# USB0_VBP2AHB_WRAP_CONTROLLER_VBP_USB3_CORE_GBL register map
Vendor: Texas Instruments
Registers are 32-bit, read-write, reset 0x0 unless marked. A register's access mark holds for its fields unless they carry their own. Offsets are as the file gives them; [hi:lo] are bit positions; {n}, {i} and the like mark numbered series; <NAME> marks a mode.

## USB0_VBP2AHB_WRAP_CONTROLLER_VBP_USB3_CORE_GBL (part 3 of 4)
0x20 VBP2AHB_WRAP__CONTROLLER_VBP__USB3_CORE_GBL_GSNPSID ro reset 0x5533330B — Global Synopsys ID Register This is a read-only register that contains the release number of the controller.
  [31:0] SYNOPSYSID — Synopsys ID - SynopsysID[31:16] indicates Core Identification Number. 0x5533 is ASCII for U3 [DWC_usb3]. - SynopsysID[15:0] indicates the release number. Current Release is 3.30a. Software uses this register to configure release-specific features in the driver.
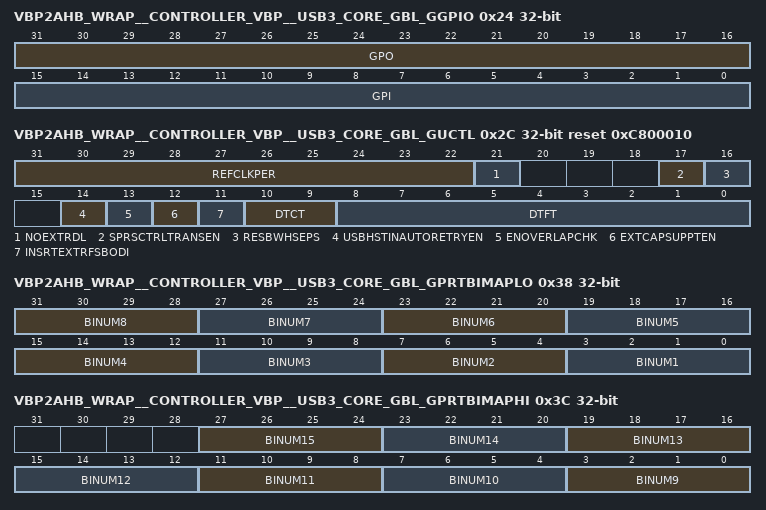
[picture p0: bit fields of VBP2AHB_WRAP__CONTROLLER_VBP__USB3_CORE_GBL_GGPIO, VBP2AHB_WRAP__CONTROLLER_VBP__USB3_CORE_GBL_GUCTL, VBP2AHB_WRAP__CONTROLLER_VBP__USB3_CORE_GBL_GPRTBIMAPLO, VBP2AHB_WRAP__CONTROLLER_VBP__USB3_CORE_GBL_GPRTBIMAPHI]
0x24 VBP2AHB_WRAP__CONTROLLER_VBP__USB3_CORE_GBL_GGPIO access per field — Global General Purpose Input/Output Register The application can use this register for general purpose input and output ports or for debugging.
  [31:16] GPO rw — General Purpose Output The value of this field is driven out on the gp_out[15:0] output port.
  [15:0] GPI ro — General Purpose Input The read value of this field reflects the gp_in[15:0] input signal value. Note: Register bit-bash test should not check for reset value of this field since its not predictable. depends on the gp_in port.
0x28 VBP2AHB_WRAP__CONTROLLER_VBP__USB3_CORE_GBL_GUID — Global User ID Register This is a read/write register containing the User ID. The power-on value for this register is specified as the User Identification Register. Power-on value during coreConsultant configuration (parameter DWC_USB3_USERID). This register can be used in the following ways: - To store the version or revision of your system. - To store hardware configurations that are outside the controller. - As a scratch register.
  [31:0] USERID — USERID Application-programmable ID field.
0x2C VBP2AHB_WRAP__CONTROLLER_VBP__USB3_CORE_GBL_GUCTL reset 0xC800010 — Global User Control Register: This register provides a few options for the software to control the controller behavior in the Host mode. Most of the options are used to improve host inter-operability with different devices.
  [31:22] REFCLKPER — REFCLKPER This field indicates in terms of nano seconds the period of ref_clk. The default value of this register is set to 'h8 [8ns/125 MHz]. This field needs to be updated during power-on initialization, if GCTL.SOFITPSYNC or GFLADJ.GFLADJ_REFCLK_LPM_SEL is set to '1'. The programmable maximum value is 62ns, and the minimum value is 8ns. You must use a reference clock with a period that is an integer multiple, so that ITP can meet the jitter margin of 32ns. The allowable ref_clk frequencies whose period is not integer multiples are 16/17/19.2/24/39.7MHz. This field must not be set to '0' at any time. If you never plan to use this feature, then set this field to 'h8, the default value.
  [21] NOEXTRDL — No Extra Delay Between SOF and the First Packet[NoExtrDl] Some HS devices misbehave when the host sends a packet immediately after a SOF. However, adding an extra delay between a SOF and the first packet can reduce the USB data rate and performance. This bit is used to control whether the host must wait for 2 microseconds before it sends the first packet after a SOF, or not. User can set this bit to one to improve the performance if those problematic devices are not a concern in the user's host environment. - 1'b0: Host waits for 2 microseconds after a SOF before it sends the first USB packet. - 1'b1: Host doesn't wait after a SOF before it sends the first USB packet.
  [17] SPRSCTRLTRANSEN — Sparse Control Transaction Enable Some devices are slow in responding to Control transfers. Scheduling multiple transactions in one microframe/frame can cause these devices to misbehave. If this bit is set to 1'b1, the host controller schedules transactions for a Control transfer in different microframes/frames.
  [16] RESBWHSEPS — Reserving 85% Bandwidth for HS Periodic EPs [ResBwHSEPS] By default, HC reserves 800f the bandwidth for periodic EPs. If this bit is set, the bandwidth is relaxed to 85% to accommodate two high speed, high bandwidth ISOC EPs. USB 2.0 required 800andwidth allocated for ISOC traffic. If two High-bandwidth ISOC devices [HD Webcams] are connected, and if each requires 1024-bytes X 3 packets per Micro-Frame, then the bandwidth required is around 82%. If this bit is set, then it is possible to connect two Webcams of 1024bytes X 3 paylod per Micro-Frame each. Otherwise, you may have to reduce the resolution of the Webcams. This bit is valid in Host and DRD configuration and is used in host mode operation only. Ignore this bit in device mode.
  [14] USBHSTINAUTORETRYEN — Host IN Auto Retry [USBHstInAutoRetryEn] When set, this field enables the Auto Retry feature. For IN transfers [non-isochronous] that encounter data packets with CRC errors or internal overrun scenarios, the auto retry feature causes the Host controller to reply to the device with a non-terminating retry ACK [that is, an ACK transaction packet with Retry = 1 and NumP != 0]. If the Auto Retry feature is disabled [default], the controller will respond with a terminating retry ACK [that is, an ACK transaction packet with Retry = 1 and NumP = 0]. - 1'b0: Auto Retry Disabled - 1'b1: Auto Retry Enabled Note: When enabling Auto Retry feature, if the system latency is large enough to cause the internal PSQ full [PSQ can be full as the result of messages not being processed because of pending fetches before flushing the TxQ due to NRDY/ERDY conditions], then the host controller can generate a transaction error.
  [13] ENOVERLAPCHK — Enable Check for LFPS Overlap During Remote Ux Exit: If this bit is set to, - 1'b1: The SuperSpeed link when exiting U1/U2/U3 waits for either the remote link LFPS or TS1/TS2 training symbols before it confirms that the LFPS handshake is complete. This is done to handle the case where the LFPS glitch causes the link to start exiting from the low power state. Looking for the LFPS overlap makes sure that the link partner also sees the LFPS. - 1'b0: When the link exists U1/U2/U3 because of a remote exit, it does not look for an LFPS overlap.
  [12] EXTCAPSUPPTEN — External Extended Capability Support Enable [ExtCapSuptEN] When set, this field enables extended capabilities to be implemented outside the controller. When the ExtCapSupEN is set and the Debug Capability is enabled, the Next Capability pointer in Debug Capability returns 16. A read to the first DWORD of the last internal extended capability [the xHCI Supported Protocol Capability for USB 3.0 when the Debug Capability is not enabled] returns a value of 4 in the Next Capability Pointer field. This indicates to software that there is another capability four DWORDs after this capability [for example, at address N+16 where N is the address of this DWORD]. If enabled, an external address decoder that snoops the xHC target interface must be implemented. If it sees an access to N+16 or greater, the target access is re-routed to a piece of hardware which returns the external capability pointer register of the new capability and also handles reads/writes to this new capability and the side effects. If disabled, a read to the first DWORD of the last internal extended capability returns 0 in the 'Next Capability Pointer field. This indicates there are no more capabilities.
  [11] INSRTEXTRFSBODI — Insert Extra Delay Between FS Bulk OUT Transactions [InsrtExtrFSBODl]. Some FS devices are slow to receive Bulk OUT data and can get stuck when there are consecutive Bulk OUT transactions with short inter-transaction delays. This bit is used to control whether the host inserts extra delay between consecutive Bulk OUT transactions to a FS Endpoint. - 1'b0: Host doesn't insert extra delay between consecutive Bulk OUT transactions to a FS Endpoint. - 1'b1: Host inserts about 12us extra delay between consecutive Bulk OUT transactions to a FS Endpoint to work around the device issue. Note: Setting this bit to one will reduce the Bulk OUT transfer performance for most of the FS devices.
  [10:9] DTCT — Device Timeout Coarse Tuning [DTCT] This field is a Host mode parameter which determines how long the host waits for a response from device before considering a timeout. The controller first checks the DTCT value. If it is 0, then the timeout value is defined by the DTFT. If it is non-zero, then it uses the following timeout values: - 2'b00: 0 usec -> use DTFT value instead - 2'b01: 500 usec - 2'b10: 1.5 msec - 2'b11: 6.5 msec Note: When the system latency is larger than the programmed DTCT/DTFT value, if the host controller is not able to accept certain transactions on the bus [because of system bus delays], the controller may not release header credits which in turn can cause the host to report a transaction error. Therefore, program this value to be larger than your system delay.
  [8:0] DTFT — Device Timeout Fine Tuning [DTFT] This field is a Host mode parameter which determines how long the host waits for a response from device before considering a timeout. For the DTFT field to take effect, DTCT must be set to 2'b00. The DTFT value is the number of 125 MHz clocks * 256 to count before considering a device timeout. The minimum value of DTFT is 2. For example, if the mac3_clk is 125 MHz clk [8 ns period], this is calculated as follows: [DTFT value] * 256 * [8 ns] Quick Reference: - if DTFT = 0x2, 2*256*8 = 4usec timeout - if DTFT = 0x5, 5*256*8 = 10usec timeout - if DTFT = 0xA, 10*256*8 = 20usec timeout - if DTFT = 0x10, 16*256*8 = 32usec timeout - if DTFT = 0x19, 25*256*8 = 51usec timeout - if DTFT = 0x31, 49*256*8 = 100usec timeout - if DTFT = 0x62, 98*256*8 = 200usec timeout Note: When the system latency is larger than the programmed DTCT/DTFT value, if the host controller is not able to accept certain transactions on the bus [because of system bus delays], the controller may not release header credits which in turn can cause the host to report a transaction error. Therefore, program this value to be larger than your system delay.
0x30 VBP2AHB_WRAP__CONTROLLER_VBP__USB3_CORE_GBL_GBUSERRADDRLO ro — Gobal SoC Bus Error Address Register - Low This is an alternate register for the GBUSERRADDR register.
  [31:0] BUSERRADDR — Bus Address - Low [BusAddrLo] This register contains the lower 32 bits of the first bus address that encountered a SoC bus error. It is valid when the GSTS.BusErrAddrVld field is 1. It can only be cleared by resetting the controller. Note: Only supported in AHB and AXI configurations.
0x34 VBP2AHB_WRAP__CONTROLLER_VBP__USB3_CORE_GBL_GBUSERRADDRHI ro — Gobal SoC Bus Error Address Register - High This is an alternate register for the GBUSERRADDR register.
  [31:0] BUSERRADDR — Bus Address - High [BusAddrHi] This register contains the higher 32 bits of the first bus address that encountered a SoC bus error. It is valid when the GSTS.BusErrAddrVld field is 1. It can only be cleared by resetting the controller. Note: Only supported in AHB and AXI configurations.
0x38 VBP2AHB_WRAP__CONTROLLER_VBP__USB3_CORE_GBL_GPRTBIMAPLO access per field — Global SS Port to Bus Instance Mapping Register - Low This is an alternate register for the GPRTBIMAP register. Register fields are read-write with respect to number of port instantiated. writeAsRead constraint is added to limit side effects for unused fields. For a configuration with number of USB 3.0 ports same as number of SS Bus Instances, do not remap during debug session. If you remap for some reason, then the debug host must be connected to a port which has a dedicated SS Bus Instance. For example, if DWC_USB3_NUM_U3_ROOT_PORTS =3 and DWC_USB3_NUM_SS_USB_INSTANCES=3, and software maps the first SS port to the first SS BI and the second/third port to the second BI, then the debug host can be connected to the first port only. Note: For reset values, refer to the corresponding values in the GPRTBIMAP register.
  [4n-1:4n-4] BINUM{n} ro (n=2..8) — BINUM{n}: SS USB Instance Number for Port {n}. Application-programmable ID field.
  [3:0] BINUM1 rw — BINUM1: SS USB Instance Number for Port 1. Application-programmable ID field.
0x3C VBP2AHB_WRAP__CONTROLLER_VBP__USB3_CORE_GBL_GPRTBIMAPHI ro — Global SS Port to Bus Instance Mapping Register - High This is an alternate register for the GPRTBIMAP register. For a configuration with number of USB 3.0 ports same as number of SS Bus Instances, do not remap during debug session. If you remap for some reason, then the debug host must be connected to a port which has a dedicated SS Bus Instance. For example, if DWC_USB3_NUM_U3_ROOT_PORTS =3 and DWC_USB3_NUM_SS_USB_INSTANCES=3, and software maps the first SS port to the first SS BI and the second/third port to the second BI, then the debug host can be connected to the first port only. Note: For reset values, refer to the corresponding values in the GPRTBIMAP register.
  [4n-33:4n-36] BINUM{n} (n=9..15) — BINUM{n}: SS USB Instance Number for Port {n}. Application-programmable ID field.
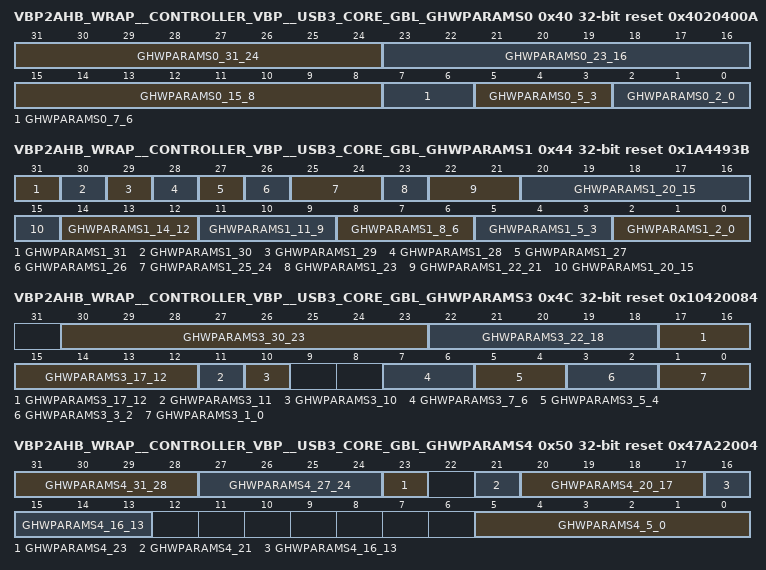
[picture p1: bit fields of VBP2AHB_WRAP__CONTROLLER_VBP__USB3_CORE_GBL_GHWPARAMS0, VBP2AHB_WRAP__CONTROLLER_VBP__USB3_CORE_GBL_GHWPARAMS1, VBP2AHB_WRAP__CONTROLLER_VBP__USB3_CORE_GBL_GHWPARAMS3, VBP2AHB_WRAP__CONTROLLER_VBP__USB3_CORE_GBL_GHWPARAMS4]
0x40 VBP2AHB_WRAP__CONTROLLER_VBP__USB3_CORE_GBL_GHWPARAMS0 ro reset 0x4020400A — Global Hardware Parameters Register 0 This register contains the hardware configuration options that you can select in the coreConsultant GUI. For a description of each parameter, refer to the Parameter Descriptions chapter in the Databook. This information is also available in coreConsultant by right-clicking the parameter label and selecting What's This or by clicking the Help tab. Note: Some of the global hardware parameters are not currently modifiable in coreConsultant. These settings are in the <workspace>/src/DWC_usb3_params.v file. you must not change them.
  [31:24] GHWPARAMS0_31_24 — DWC_USB3_AWIDTH
  [23:16] GHWPARAMS0_23_16 — DWC_USB3_SDWIDTH
  [15:8] GHWPARAMS0_15_8 — DWC_USB3_MDWIDTH
  [7:6] GHWPARAMS0_7_6 — DWC_USB3_SBUS_TYPE
  [5:3] GHWPARAMS0_5_3 — DWC_USB3_MBUS_TYPE
  [2:0] GHWPARAMS0_2_0 — DWC_USB3_MODE
0x44 VBP2AHB_WRAP__CONTROLLER_VBP__USB3_CORE_GBL_GHWPARAMS1 ro reset 0x1A4493B — Global Hardware Parameters Register 1 This register contains the hardware configuration options that you can select in the coreConsultant GUI. For a description of each parameter, refer to the Parameter Descriptions chapter in the Databook. This information is also available in coreConsultant by right-clicking the parameter label and selecting What's This or by clicking the Help tab. Note: Some of the global hardware parameters are not currently modifiable in coreConsultant. These settings are in the <workspace>/src/DWC_usb3_params.v file. you must not change them.
  [31] GHWPARAMS1_31 — DWC_USB3_EN_DBC
  [30] GHWPARAMS1_30 — DWC_USB3_RM_OPT_FEATURES
  [29] GHWPARAMS1_29 — Reserved1
  [28] GHWPARAMS1_28 — DWC_USB3_RAM_BUS_CLKS_SYNC
  [27] GHWPARAMS1_27 — DWC_USB3_MAC_RAM_CLKS_SYNC
  [26] GHWPARAMS1_26 — DWC_USB3_MAC_PHY_CLKS_SYNC
  [25:24] GHWPARAMS1_25_24 — DWC_USB3_EN_PWROPT
  [23] GHWPARAMS1_23 — DWC_USB3_SPRAM_TYP
  [22:21] GHWPARAMS1_22_21 — DWC_USB3_NUM_RAMS
  [20:15] GHWPARAMS1_20_15 — DWC_USB3_DEVICE_NUM_INT For details on DWC_USB3_DEVICE_NUM_INT, refer to <workspace>/src/DWC_usb3_params.v file.
  [14:12] GHWPARAMS1_14_12 — DWC_USB3_ASPACEWIDTH
  [11:9] GHWPARAMS1_11_9 — DWC_USB3_REQINFOWIDTH
  [8:6] GHWPARAMS1_8_6 — DWC_USB3_DATAINFOWIDTH
  [5:3] GHWPARAMS1_5_3 — DWC_USB3_BURSTWIDTH-1
  [2:0] GHWPARAMS1_2_0 — DWC_USB3_IDWIDTH-1
0x48 VBP2AHB_WRAP__CONTROLLER_VBP__USB3_CORE_GBL_GHWPARAMS2 ro — Global Hardware Parameters Register 2 This register contains the hardware configuration options that you can select in the coreConsultant GUI. For a description of each parameter, refer to the Parameter Descriptions chapter in the Databook. This information is also available in coreConsultant by right-clicking the parameter label and selecting What's This or by clicking the Help tab. Note: Some of the global hardware parameters are not currently modifiable in coreConsultant. These settings are in the <workspace>/src/DWC_usb3_params.v file. you must not change them.
  [31:0] GHWPARAMS2_31_0 — DWC_USB3_USERID
0x4C VBP2AHB_WRAP__CONTROLLER_VBP__USB3_CORE_GBL_GHWPARAMS3 ro reset 0x10420084 — Global Hardware Parameters Register 3 This register contains the hardware configuration options that you can select in the coreConsultant GUI. For a description of each parameter, refer to the Parameter Descriptions chapter in the Databook. This information is also available in coreConsultant by right-clicking the parameter label and selecting What's This or by clicking the Help tab. Note: Some of the global hardware parameters are not currently modifiable in coreConsultant. These settings are in the <workspace>/src/DWC_usb3_params.v file. you must not change them.
  [30:23] GHWPARAMS3_30_23 — DWC_USB3_CACHE_TOTAL_XFER_RESOURCES
  [22:18] GHWPARAMS3_22_18 — DWC_USB3_NUM_IN_EPS
  [17:12] GHWPARAMS3_17_12 — DWC_USB3_NUM_EPS
  [11] GHWPARAMS3_11 — DWC_USB3_ULPI_CARKIT
  [10] GHWPARAMS3_10 — DWC_USB3_VENDOR_CTL_INTERFACE
  [7:6] GHWPARAMS3_7_6 — DWC_USB3_HSPHY_DWIDTH
  [5:4] GHWPARAMS3_5_4 — DWC_USB3_FSPHY_INTERFACE
  [3:2] GHWPARAMS3_3_2 — DWC_USB3_HSPHY_INTERFACE
  [1:0] GHWPARAMS3_1_0 — DWC_USB3_SSPHY_INTERFACE
0x50 VBP2AHB_WRAP__CONTROLLER_VBP__USB3_CORE_GBL_GHWPARAMS4 ro reset 0x47A22004 — Global Hardware Parameters Register 4 This register contains the hardware configuration options that you can select in the coreConsultant GUI. For a description of each parameter, refer to the Parameter Descriptions chapter in the Databook. This information is also available in coreConsultant by right-clicking the parameter label and selecting What's This or by clicking the Help tab. Note: Some of the global hardware parameters are not currently modifiable in coreConsultant. These settings are in the <workspace>/src/DWC_usb3_params.v file. you must not change them.
  [31:28] GHWPARAMS4_31_28 — DWC_USB3_BMU_LSP_DEPTH
  [27:24] GHWPARAMS4_27_24 — DWC_USB3_BMU_PTL_DEPTH-1
  [23] GHWPARAMS4_23 — DWC_USB3_EN_ISOC_SUPT
  [21] GHWPARAMS4_21 — DWC_USB3_EXT_BUFF_CONTROL
  [20:17] GHWPARAMS4_20_17 — DWC_USB3_NUM_SS_USB_INSTANCES
  [16:13] GHWPARAMS4_16_13 — DWC_USB3_HIBER_SCRATCHBUFS Number of external scratchpad buffers the controller requires to save its internal state in the device mode. Each buffer is assumed to be 4KB. The scratchpad buffer array must have this many buffer pointers.
  [5:0] GHWPARAMS4_5_0 — DWC_USB3_CACHE_TRBS_PER_TRANSFER
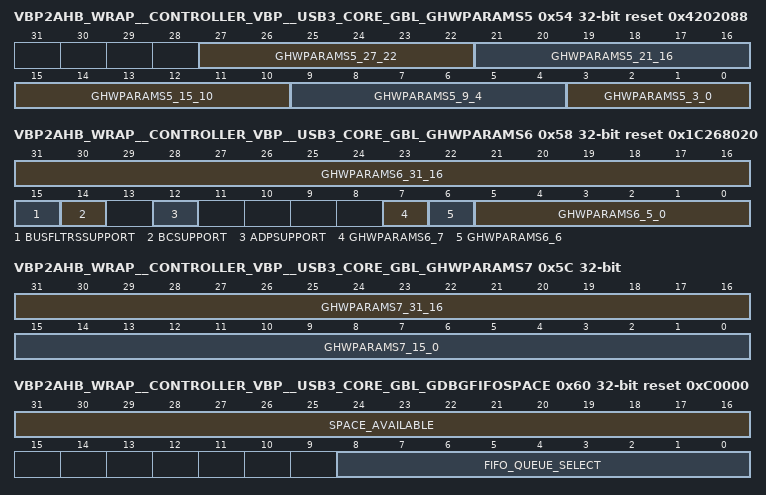
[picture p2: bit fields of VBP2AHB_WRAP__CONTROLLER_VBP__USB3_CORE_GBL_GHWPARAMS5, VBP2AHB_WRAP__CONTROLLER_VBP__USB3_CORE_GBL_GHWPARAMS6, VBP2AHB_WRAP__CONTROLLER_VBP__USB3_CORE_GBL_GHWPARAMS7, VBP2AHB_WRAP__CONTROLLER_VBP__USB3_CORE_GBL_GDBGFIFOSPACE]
0x54 VBP2AHB_WRAP__CONTROLLER_VBP__USB3_CORE_GBL_GHWPARAMS5 ro reset 0x4202088 — Global Hardware Parameters Register 5 This register contains the hardware configuration options that you can select in the coreConsultant GUI. For a description of each parameter, refer to the Parameter Descriptions chapter in the Databook. This information is also available in coreConsultant by right-clicking the parameter label and selecting What's This or by clicking the Help tab. Note: Some of the global hardware parameters are not currently modifiable in coreConsultant. These settings are in the <workspace>/src/DWC_usb3_params.v file. you must not change them.
  [27:22] GHWPARAMS5_27_22 — DWC_USB3_DFQ_FIFO_DEPTH
  [21:16] GHWPARAMS5_21_16 — DWC_USB3_DWQ_FIFO_DEPTH
  [15:10] GHWPARAMS5_15_10 — DWC_USB3_TXQ_FIFO_DEPTH
  [9:4] GHWPARAMS5_9_4 — DWC_USB3_RXQ_FIFO_DEPTH
  [3:0] GHWPARAMS5_3_0 — DWC_USB3_BMU_BUSGM_DEPTH
0x58 VBP2AHB_WRAP__CONTROLLER_VBP__USB3_CORE_GBL_GHWPARAMS6 ro reset 0x1C268020 — Global Hardware Parameters Register 6 This register contains the hardware configuration options that you can select in the coreConsultant GUI. For a description of each parameter, refer to the Parameter Descriptions chapter in the Databook. This information is also available in coreConsultant by right-clicking the parameter label and selecting What's This or by clicking the Help tab. Note: Some of the global hardware parameters are not currently modifiable in coreConsultant. These settings are in the <workspace>/src/DWC_usb3_params.v file. you must not change them.
  [31:16] GHWPARAMS6_31_16 — DWC_USB3_RAM0_DEPTH
  [15] BUSFLTRSSUPPORT — DWC_USB3_EN_BUS_FILTERS
  [14] BCSUPPORT — DWC_USB3_EN_BC
  [12] ADPSUPPORT — DWC_USB3_EN_ADP
  [7] GHWPARAMS6_7 — DWC_USB3_EN_FPGA
  [6] GHWPARAMS6_6 — DWC_USB3_EN_DBG_PORTS
  [5:0] GHWPARAMS6_5_0 — DWC_USB3_PSQ_FIFO_DEPTH
0x5C VBP2AHB_WRAP__CONTROLLER_VBP__USB3_CORE_GBL_GHWPARAMS7 ro — Global Hardware Parameters Register 7 This register contains the hardware configuration options that you can select in the coreConsultant GUI. For a description of each parameter, refer to the Parameter Descriptions chapter in the Databook. This information is also available in coreConsultant by right-clicking the parameter label and selecting What's This or by clicking the Help tab. Note: Some of the global hardware parameters are not currently modifiable in coreConsultant. These settings are in the <workspace>/src/DWC_usb3_params.v file. you must not change them.
  [31:16] GHWPARAMS7_31_16 — DWC_USB3_RAM2_DEPTH
  [15:0] GHWPARAMS7_15_0 — DWC_USB3_RAM1_DEPTH
0x60 VBP2AHB_WRAP__CONTROLLER_VBP__USB3_CORE_GBL_GDBGFIFOSPACE access per field reset 0xC0000 — Global Debug Queue/FIFO Space Available Register Bit Bash test should not be done on this debug register.
  [31:16] SPACE_AVAILABLE ro
  [8:0] FIFO_QUEUE_SELECT rw — FIFO/Queue Select [or] Port-Select - FIFO/Queue Select[8:5] indicates the FIFO/Queue Type - FIFO/Queue Select[4:0] indicates the FIFO/Queue Number For example, 9'b0_0010_0001 refers to RxFIFO_1 and 9'b0_0101_1110 refers to TxReqQ_30. - 9'b0_0001_1111 to 9'b0_0000_0000: TxFIFO_31 to TxFIFO_0 - 9'b0_0011_1111 to 9'b0_0010_0000: RxFIFO_31 to RxFIFO_0 - 9'b0_0101_1111 to 9'b0_0100_0000: TxReqQ_31 to TxReqQ_0 - 9'b0_0111_1111 to 9'b0_0110_0000: RxReqQ_31 to RxReqQ_0 - 9'b0_1001_1111 to 9'b0_1000_0000: RxInfoQ_31 to RxInfoQ_0 - 9'b0_1010_0000: DescFetchQ_0 [for backwards compatibility] - 9'b0_1010_0001: EventQ_0 [for backwards compatibility] - 9'b0_1010_0010: ProtocolStatusQ_0 - 9'b0_1101_1111 to 9'b0_1110_0000: DescFetchQ_31 to DescFetchQ_0 - 9'b0_1111_1111 to 9'b0_1110_0000: WriteBack/EventQ_31 to WriteBack/EventQ_0 - 9'b1_0000_0111 to 9'b1_0000_0000: AuxEventQ_7 to AuxEventQ_0 [if EN_SEPARATE_DESC_QUEUES=1] Port-Select[3:0] selects the port-number when accessing GDBGLTSSM register.
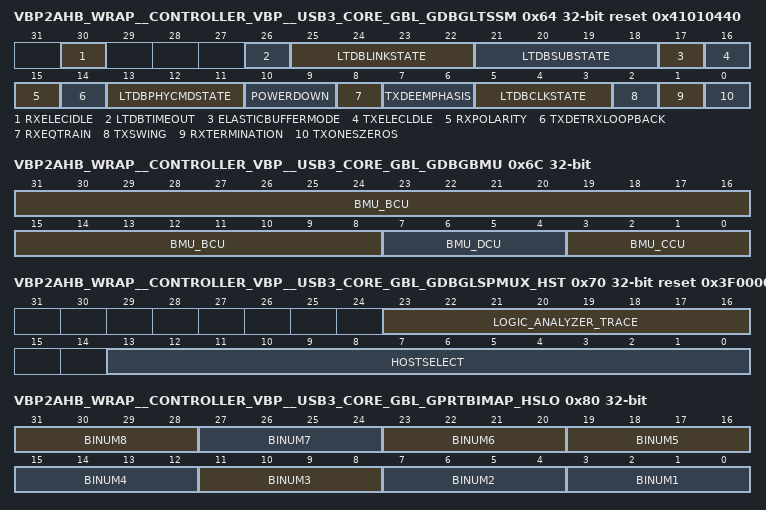
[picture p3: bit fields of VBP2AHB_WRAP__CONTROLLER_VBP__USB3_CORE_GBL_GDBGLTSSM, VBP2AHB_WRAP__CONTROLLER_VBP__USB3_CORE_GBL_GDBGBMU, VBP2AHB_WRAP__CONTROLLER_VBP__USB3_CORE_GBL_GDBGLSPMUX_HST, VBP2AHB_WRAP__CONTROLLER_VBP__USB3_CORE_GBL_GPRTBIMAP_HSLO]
0x64 VBP2AHB_WRAP__CONTROLLER_VBP__USB3_CORE_GBL_GDBGLTSSM ro reset 0x41010440 — Global Debug LTSSM Register In multi-port host configuration, the port-number is defined by Port-Select[3:0] field in the GDBGFIFOSPACE register. Note: - GDBGLTSSM register is not applicable for USB 2.0-only mode. - Bit Bash test should not be done on this debug register.
  [30] RXELECIDLE — RxElecidle For description of RxElecIdle, see table 5-4, Status Interface Signals of the PIPE3 Specification.
  [26] LTDBTIMEOUT — LTDB Timeout [LTDBTimeout]
  [25:22] LTDBLINKSTATE — LTDB Link State [LTDBLinkState]
  [21:18] LTDBSUBSTATE — LTDB Sub-State [LTDBSubState]
  [17] ELASTICBUFFERMODE — Elastic Buffer Mode [ElasticBufferMode] For field definition, refer to Table 5-3 of the PIPE3 specification.
  [16] TXELECLDLE — Tx Elec Idle [TxElecIdle] For field definition, refer to Table 5-3 of the PIPE3 specification.
  [15] RXPOLARITY — Rx Polarity [RxPolarity] For field definition, refer to Table 5-3 of the PIPE3 specification.
  [14] TXDETRXLOOPBACK — Tx Detect Rx/Loopback [TxDetRxLoopback] For field definition, refer to Table 5-3 of the PIPE3 specification.
  [13:11] LTDBPHYCMDSTATE — LTSSM PHY command State [LTDBPhyCmdState] - 000: PHY_IDLE [PHY command state is in IDLE. No PHY request pending] - 001: PHY_DET [Request to start Receiver detection] - 010: PHY_DET_3 [Wait for Phy_Status [Receiver detection]] - 011: PHY_PWR_DLY [Delay Pipe3_PowerDown P0 -> P1/P2/P3 request] - 100: PHY_PWR_A [Delay for internal logic] - 101: PHY_PWR_B [Wait for Phy_Status[Power state change request]]
  [10:9] POWERDOWN — POWERDOWN [PowerDown] For field definition, refer to Table 5-3 of the PIPE3 specification.
  [8] RXEQTRAIN — RxEq Train For field definition, refer to Table 5-3 of the PIPE3 specification.
  [7:6] TXDEEMPHASIS — TXDEEMPHASIS [TxDeemphasis] For field definition, refer to Table 5-3 of the PIPE3 specification.
  [5:3] LTDBCLKSTATE — LTSSM Clock State [LTDBClkState] In multi-port host configuration, the port number is defined by Port-Select[3:0] field in the GDBGFIFOSPACE register. Note: GDBGLTSSM register is not applicable for USB 2.0-only mode. - 000: CLK_NORM [PHY is in non-P3 state and PCLK is running] - 001: CLK_TO_P3 [P3 entry request to PHY]. - 010: CLK_WAIT1 [Wait for Phy_Status [P3 request]]. - 011: CLK_P3 [PHY is in P3 and PCLK is not running]. - 100: CLK_TO_P0 [P3 exit request to PHY]. - 101: CLK_WAIT2 [Wait for Phy_Status [P3 exit request]]
  [2] TXSWING — Tx Swing [TxSwing] For field definition, refer to Table 5-3 of the PIPE3 specification.
  [1] RXTERMINATION — Rx Termination [RxTermination] For details on DWC_USB3_PIPE_RXTERM_RESET_VAL, refer to <workspace>/src/DWC_usb3_params.v
  [0] TXONESZEROS — Tx Ones/Zeros [TxOnesZeros] For field definition, refer to Table 5-3 of the PIPE3 specification.
0x68 VBP2AHB_WRAP__CONTROLLER_VBP__USB3_CORE_GBL_GDBGLNMCC ro — Global Debug LNMCC Register Bit Bash test should not be done on this debug register.
  [8:0] LNMCC_BERC — This field indicates the bit error rate information for the port selected in the GDBGFIFOSPACE.PortSelect field. This field is for debug purposes only.
0x6C VBP2AHB_WRAP__CONTROLLER_VBP__USB3_CORE_GBL_GDBGBMU ro — Global Debug BMU Register Bit Bash test should not be done on this debug register.
  [31:8] BMU_BCU — BMU_BCU Debug information
  [7:4] BMU_DCU — BMU_DCU Debug information
  [3:0] BMU_CCU — BMU_CCU Debug information
0x70 VBP2AHB_WRAP__CONTROLLER_VBP__USB3_CORE_GBL_GDBGLSPMUX_HST reset 0x3F0000 — Global Debug LSP MUX Register - Host This register is for internal use only. If DWC_USB3_PRESERVE_LOGIC_ANALYZER_SELECT is enabled during controller configuration, then the default values readout is X (Undefined). Bit Bash test should not be done on this debug register.
  [23:16] LOGIC_ANALYZER_TRACE — logic_analyzer_trace Port MUX Select Currently only bits[21:16] are used. For details on how the mux controls the debug traces, refer to the assign logic_analyzer_trace = code section in the DWC_usb3.v file. A value of 6'h3F drives 0s on the logic_analyzer_trace signal. If you plan to OR [instead using a mux] this signal with other trace signals in your system to generate a common trace signal, you can use this feature.
  [13:0] HOSTSELECT — Device LSP Select Selects the LSP debug information presented in the GDBGLSP register in host mode.
0x74 VBP2AHB_WRAP__CONTROLLER_VBP__USB3_CORE_GBL_GDBGLSP ro — Global Debug LSP Register This register is for internal debug purposes only. This register is for internal use only. If DWC_USB3_PRESERVE_LOGIC_ANALYZER_SELECT is enabled during controller configuration, then the default values readout is X (Undefined). Bit Bash test should not be done on this debug register.
  [31:0] LSPDEBUG — LSP Debug Information
0x78 VBP2AHB_WRAP__CONTROLLER_VBP__USB3_CORE_GBL_GDBGEPINFO0 ro — Global Debug Endpoint Information Register 0 This register is for internal use only. If DWC_USB3_PRESERVE_LOGIC_ANALYZER_SELECT is enabled during controller configuration, then the default values readout is X (Undefined). Bit Bash test should not be done on this debug register.
  [31:0] EPDEBUG — Endpoint Debug Information, bits[31:0]
0x7C VBP2AHB_WRAP__CONTROLLER_VBP__USB3_CORE_GBL_GDBGEPINFO1 ro reset 0x800000 — Global Debug Endpoint Information Register 1 This register is for internal use only. If DWC_USB3_PRESERVE_LOGIC_ANALYZER_SELECT is enabled during controller configuration, then the default values readout is X (Undefined). Bit Bash test should not be done on this debug register.
  [31:0] EPDEBUG — Endpoint Debug Information, bits[63:32]
0x80 VBP2AHB_WRAP__CONTROLLER_VBP__USB3_CORE_GBL_GPRTBIMAP_HSLO access per field — Global High-Speed Port to Bus Instance Mapping Register - Low This is an alternate register for the GPRTBIMAP_HS register. - Register fields are read-write with respect to number of port instantiated. writeAsRead constraint is added to limit side effects for unused fields. Note: For reset values, refer to the corresponding values in the GPRTBIMAP_HS register.
  [31:28] BINUM8 ro — BINUM8: HS USB Instance Number for Port 8. Application-programmable ID field.
  [27:24] BINUM7 ro — BINUM7: HS USB Instance Number for Port 7. Application-programmable ID field.
  [23:20] BINUM6 ro — BINUM6 USB Instance Number for Port 6. Application-programmable ID field.
  [4n-1:4n-4] BINUM{n} ro (n=2..5) — BINUM{n}: HS USB Instance Number for Port {n}. Application-programmable ID field.
  [3:0] BINUM1 rw — BINUM1: HS USB Instance Number for Port 1. Application-programmable ID field.
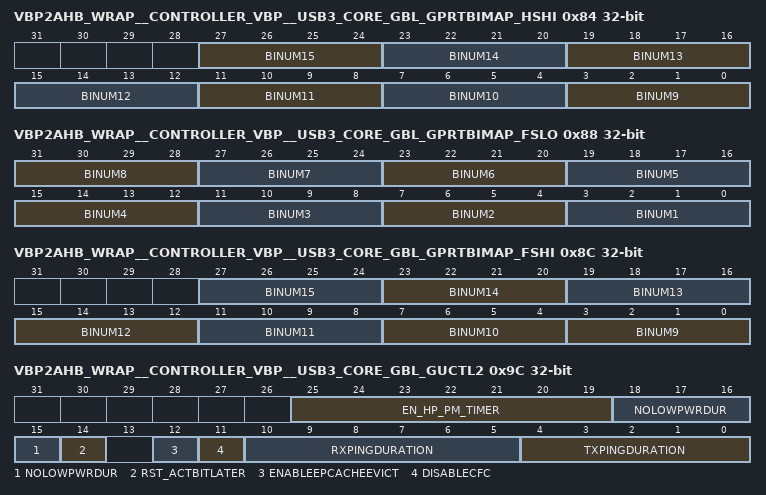
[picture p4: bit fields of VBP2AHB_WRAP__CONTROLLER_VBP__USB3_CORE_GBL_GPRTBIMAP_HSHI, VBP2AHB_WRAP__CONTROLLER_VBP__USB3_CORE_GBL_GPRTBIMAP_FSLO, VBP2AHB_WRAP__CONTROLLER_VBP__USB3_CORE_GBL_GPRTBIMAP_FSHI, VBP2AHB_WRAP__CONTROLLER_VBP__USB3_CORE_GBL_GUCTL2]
0x84 VBP2AHB_WRAP__CONTROLLER_VBP__USB3_CORE_GBL_GPRTBIMAP_HSHI ro — Global High-Speed Port to Bus Instance Mapping Register - High This is an alternate register for the GPRTBIMAP_HS register. - Register fields are read-write with respect to number of port instantiated. writeAsRead constraint is added to limit side effects for unused fields. Note: For reset values, refer to the corresponding values in the GPRTBIMAP register.
  [27:24] BINUM15 — BINUM15: HS USB Instance Number for Port 15. Application-programmable ID field.
  [23:20] BINUM14 — BINUM14: HS USB Instance Number for Port 14. Application-programmable ID field.
  [19:16] BINUM13 — BINUM13: HS USB Instance Number for Port 13. Application-programmable ID field.
  [15:12] BINUM12 — BINUM12: HS USB Instance Number for Port 12. SApplication-programmable ID field.
  [11:8] BINUM11 — BINUM11: HS USB Instance Number for 11. Application-programmable ID field.
  [7:4] BINUM10 — BINUM10: HS USB Instance Number for Port 10. Application-programmable ID field.
  [3:0] BINUM9 — BINUM9: HS USB Instance Number for Port 9. Application-programmable ID field.
0x88 VBP2AHB_WRAP__CONTROLLER_VBP__USB3_CORE_GBL_GPRTBIMAP_FSLO access per field — Global Full-Speed Port to Bus Instance Mapping Register - Low This is an alternate register for the GPRTBIMAP_FS register. - Register fields are read-write with respect to number of port instantiated. writeAsRead constraint is added to limit side effects for unused fields. Note: For reset values, refer to the corresponding values in the GPRTBIMAP_FS register.
  [4n-1:4n-4] BINUM{n} ro (n=2..8) — BINUM{n}: FS USB Instance Number for Port {n}. Application-programmable ID field.
  [3:0] BINUM1 rw — BINUM1: FS USB Instance Number for Port 1. Application-programmable ID field.
0x8C VBP2AHB_WRAP__CONTROLLER_VBP__USB3_CORE_GBL_GPRTBIMAP_FSHI ro — Global Full-Speed Port to Bus Instance Mapping Register - High This is an alternate register for the GPRTBIMAP_FS register. - Register fields are read-write with respect to number of port instantiated. writeAsRead constraint is added to limit side effects for unused fields. Note: For reset values, refer to the corresponding values in the GPRTBIMAP_FS register.
  [4n-33:4n-36] BINUM{n} (n=10..15) — BINUM{n}: FS USB Instance Number for Port {n}. Application-programmable ID field
  [3:0] BINUM9 — BINUM9: FS USB Instance Number for Port 9. Application-programmable ID field.
0x94 VBP2AHB_WRAP__CONTROLLER_VBP__USB3_CORE_GBL_Reserved_94 access not given — Future Reserved Register at offset 0x94
  [31:0] RESERVED — Future use Register field (access N/A)
0x98 VBP2AHB_WRAP__CONTROLLER_VBP__USB3_CORE_GBL_Reserved_98 access not given — Future Reserved Register at offset 0x98
  [31:0] RESERVED — Field for future use (access N/A)
0x9C VBP2AHB_WRAP__CONTROLLER_VBP__USB3_CORE_GBL_GUCTL2 access not given — Global User Control Register 2: This register provides a few options for the software to control the controller behavior in the Host and device mode. Most of the options are used to improve inter-operability with different hosts and devices.
  [25:19] EN_HP_PM_TIMER rw — This register field is used to set new HP and PM timers. - To enable PM timer, set GUCTL2[19] bit as 1. - To enable HP timer, set GUCTL2[20] bit as 1. Default value of HP timer is 4us when HP PM timer is not enabled. when new HP timer is enabled default value is 12us. Use GUCTL2[25:21] to specify HP timer value in microseconds.
  [18:15] NOLOWPWRDUR rw — No Low Power Duration [NOLOWPWRDUR] This bit is applicable for device mode only and is ignored in host mode. After starting a transfer on a SS ISOC endpoint, the application must program these bits to prevent the device to lose frame synchronization over a period of time. Based on this count-down counter, the device will wake itself from U1/U2 low power states. After entering to U0 state and receiving two ITPs [which will sync-up the host and the device], U1/U2 low power entry is allowed. Each count represents the duration in terms of milliseconds. For example, a value of 3 represents 3ms. Note: - To disable this feature, set this field to 4'b0. - These bits are applicable only in device mode and ignored in host mode. - Some xHCI hosts do not send ITPs when performing ISOC transfers when the link enters U1/U2 low power states. This causes the device to lose frame synchronization over a period of time resulting in ISOC packets being dropped.
  [14] RST_ACTBITLATER rw — Enable clearing of the command active bit for the ENDXFER command after the command execution is completed. This bit is valid in device mode only.
  [12] ENABLEEPCACHEEVICT rw — Enable Evicting Endpoint cache after Flow Control for bulk endpoints. In 3.00a release, a performance enhancement was done to keep the non-stream capable bulk IN endpoint in cache after flow control. Setting this bit will disable this enhancement. This should be set only for debug purpose.
  [11] DISABLECFC rw — Disable xHCI Errata Feature Contiguous Frame ID Capability This field controls the xHCI Errata feature Contiguous FrameID capability. When set, the xHCI HCCPARAMS1 bit 11 will be set to 0 indicating that CFC is not supported. Disable this feature only if your application cannot tolerate Misssed Service Error events for Isoc transfers, and your system latencies are large to cause Missed Service errors even if the software is following the Isochronous Thresholding rules.
  [10:5] RXPINGDURATION rw — Recieve Ping Maximum Duration This field is relevant to Host mode and controls the maximum duration of received LFPS to be treated as a Ping LFPS. The Max duration of the Ping LFPS is controlled by programming this value and is in terms of 8 ns granularity. Eg: A value of 32 indicates 256 ns.
  [4:0] TXPINGDURATION rw — Transmit Ping Maximum Duration This field is relevant to Device mode and controls the maximum duration for which the controller should instruct the PHY to transmit a Ping LFPS. The duration of the Ping LFPS is controlled by programming this value and is in terms of 8 ns granularity. Eg: A value of 13 indicates 104 ns.
